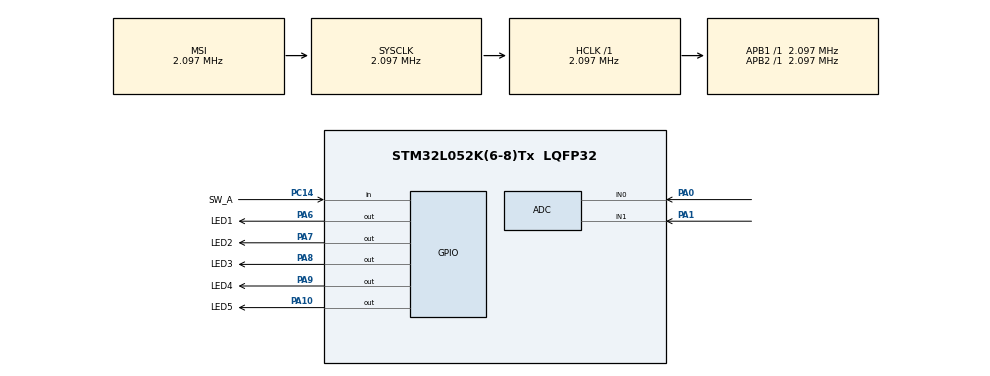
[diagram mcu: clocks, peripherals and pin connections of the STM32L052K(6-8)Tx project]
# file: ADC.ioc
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ADC.SamplingTime=ADC_SAMPLETIME_160CYCLES_5
Mcu.Family=STM32L0
Mcu.Name=STM32L052K(6-8)Tx
Mcu.Package=LQFP32
PA0.Mode=IN0
PA0.Signal=ADC_IN0
PA1.Mode=IN1
PA1.Signal=ADC_IN1
PA10.GPIO_Label=LED5
PA10.Signal=GPIO_Output
PA13.Mode=Serial_Wire
PA13.Signal=SYS_SWDIO
PA14.Mode=Serial_Wire
PA14.Signal=SYS_SWCLK
PA6.GPIO_Label=LED1
PA6.Signal=GPIO_Output
PA7.GPIO_Label=LED2
PA7.Signal=GPIO_Output
PA8.GPIO_Label=LED3
PA8.Signal=GPIO_Output
PA9.GPIO_Label=LED4
PA9.Signal=GPIO_Output
PC14-OSC32_IN.GPIO_Label=SW_A
PC14-OSC32_IN.GPIO_PuPd=GPIO_PULLUP
PC14-OSC32_IN.Signal=GPIO_Input
ProjectManager.HeapSize=0x200
ProjectManager.StackSize=0x400
ProjectManager.TargetToolchain=STM32CubeIDE
RCC.AHBFreq_Value=2097000
RCC.APB1Freq_Value=2097000
RCC.APB1TimFreq_Value=2097000
RCC.APB2Freq_Value=2097000
RCC.APB2TimFreq_Value=2097000
RCC.HSI16_VALUE=16000000
RCC.HSI48_VALUE=48000000
RCC.HSI_VALUE=16000000
RCC.LSE_VALUE=32768
RCC.MSI_VALUE=2097000
RCC.SYSCLKFreq_VALUE=2097000
RCC.VCOOutputFreq_Value=48000000
board=custom

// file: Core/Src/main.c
/* USER CODE BEGIN Header */
/**
 ******************************************************************************
 * @file           : main.c
 * @brief          : Main program body
 ******************************************************************************
 * @attention
 *
 * Copyright (c) 2022 STMicroelectronics.
 * All rights reserved.
 *
 * This software is licensed under terms that can be found in the LICENSE file
 * in the root directory of this software component.
 * If no LICENSE file comes with this software, it is provided AS-IS.
 *
 ******************************************************************************
 */
/* USER CODE END Header */
#include "main.h"

/* USER CODE BEGIN PTD */
enum _bool{false, true};
typedef uint8_t boolean;
/* USER CODE END PTD */

/* USER CODE BEGIN PD */
#define SW4 HAL_GPIO_ReadPin(SW_A_GPIO_Port, SW_A_Pin)
#define LED(N, X) HAL_GPIO_WritePin(LED##N##_GPIO_Port, LED##N##_Pin, (!X))
/* USER CODE END PD */

ADC_HandleTypeDef hadc;

void SystemClock_Config(void);
static void MX_GPIO_Init(void);
static void MX_ADC_Init(void);

/* USER CODE BEGIN 0 */
void read_ADC(uint16_t *cds, uint16_t *vr){
	HAL_ADC_Start(&hadc);
	HAL_ADC_PollForConversion(&hadc, 1000);
	*cds = HAL_ADC_GetValue(&hadc);
	HAL_ADC_PollForConversion(&hadc, 1000);
	*vr = HAL_ADC_GetValue(&hadc);
	HAL_ADC_Stop(&hadc);
}
/* USER CODE END 0 */

int main(void) {
	/* USER CODE BEGIN 1 */
	uint16_t cds, vr;
	/* USER CODE END 1 */
	/* MCU Configuration--------------------------------------------------------*/

	/* Reset of all peripherals, Initializes the Flash interface and the Systick. */
	HAL_Init();

	/* Configure the system clock */
	SystemClock_Config();

	/* Initialize all configured peripherals */
	MX_GPIO_Init();
	MX_ADC_Init();

	/* Infinite loop */
	while (1) {
		read_ADC(&cds, &vr);
		vr = (uint16_t)((double)vr / 1023.75);
		LED(1, (vr == 0 || cds > 4000));
		LED(2, (vr == 1 || cds > 4000));
		LED(3, (vr == 2 || cds > 4000));
		LED(4, (vr == 3 || cds > 4000));
		LED(5, (vr == 4 || cds > 4000));

	}
}

void SystemClock_Config(void) {
	RCC_OscInitTypeDef RCC_OscInitStruct = { 0 };
	RCC_ClkInitTypeDef RCC_ClkInitStruct = { 0 };

	/** Configure the main internal regulator output voltage
	 */
	__HAL_PWR_VOLTAGESCALING_CONFIG(PWR_REGULATOR_VOLTAGE_SCALE1);

	/** Initializes the RCC Oscillators according to the specified parameters
	 * in the RCC_OscInitTypeDef structure.
	 */
	RCC_OscInitStruct.OscillatorType = RCC_OSCILLATORTYPE_MSI;
	RCC_OscInitStruct.MSIState = RCC_MSI_ON;
	RCC_OscInitStruct.MSICalibrationValue = 0;
	RCC_OscInitStruct.MSIClockRange = RCC_MSIRANGE_5;
	RCC_OscInitStruct.PLL.PLLState = RCC_PLL_NONE;
	if (HAL_RCC_OscConfig(&RCC_OscInitStruct) != HAL_OK) {
		Error_Handler();
	}

	/** Initializes the CPU, AHB and APB buses clocks
	 */
	RCC_ClkInitStruct.ClockType = RCC_CLOCKTYPE_HCLK | RCC_CLOCKTYPE_SYSCLK
			| RCC_CLOCKTYPE_PCLK1 | RCC_CLOCKTYPE_PCLK2;
	RCC_ClkInitStruct.SYSCLKSource = RCC_SYSCLKSOURCE_MSI;
	RCC_ClkInitStruct.AHBCLKDivider = RCC_SYSCLK_DIV1;
	RCC_ClkInitStruct.APB1CLKDivider = RCC_HCLK_DIV1;
	RCC_ClkInitStruct.APB2CLKDivider = RCC_HCLK_DIV1;

	if (HAL_RCC_ClockConfig(&RCC_ClkInitStruct, FLASH_LATENCY_0) != HAL_OK) {
		Error_Handler();
	}
}

static void MX_ADC_Init(void) {

	ADC_ChannelConfTypeDef sConfig = { 0 };

	/** Configure the global features of the ADC (Clock, Resolution, Data Alignment and number of conversion)
	 */
	hadc.Instance = ADC1;
	hadc.Init.OversamplingMode = DISABLE;
	hadc.Init.ClockPrescaler = ADC_CLOCK_SYNC_PCLK_DIV1;
	hadc.Init.Resolution = ADC_RESOLUTION_12B;
	hadc.Init.SamplingTime = ADC_SAMPLETIME_160CYCLES_5;
	hadc.Init.ScanConvMode = ADC_SCAN_DIRECTION_FORWARD;
	hadc.Init.DataAlign = ADC_DATAALIGN_RIGHT;
	hadc.Init.ContinuousConvMode = DISABLE;
	hadc.Init.DiscontinuousConvMode = DISABLE;
	hadc.Init.ExternalTrigConvEdge = ADC_EXTERNALTRIGCONVEDGE_NONE;
	hadc.Init.ExternalTrigConv = ADC_SOFTWARE_START;
	hadc.Init.DMAContinuousRequests = DISABLE;
	hadc.Init.EOCSelection = ADC_EOC_SINGLE_CONV;
	hadc.Init.Overrun = ADC_OVR_DATA_PRESERVED;
	hadc.Init.LowPowerAutoWait = DISABLE;
	hadc.Init.LowPowerFrequencyMode = ENABLE;
	hadc.Init.LowPowerAutoPowerOff = DISABLE;
	if (HAL_ADC_Init(&hadc) != HAL_OK) {
		Error_Handler();
	}

	/** Configure for the selected ADC regular channel to be converted.
	 */
	sConfig.Channel = ADC_CHANNEL_0;
	sConfig.Rank = ADC_RANK_CHANNEL_NUMBER;
	if (HAL_ADC_ConfigChannel(&hadc, &sConfig) != HAL_OK) {
		Error_Handler();
	}

	/** Configure for the selected ADC regular channel to be converted.
	 */
	sConfig.Channel = ADC_CHANNEL_1;
	if (HAL_ADC_ConfigChannel(&hadc, &sConfig) != HAL_OK) {
		Error_Handler();
	}

}

static void MX_GPIO_Init(void) {
	GPIO_InitTypeDef GPIO_InitStruct = { 0 };

	/* GPIO Ports Clock Enable */
	__HAL_RCC_GPIOC_CLK_ENABLE();
	__HAL_RCC_GPIOA_CLK_ENABLE();

	/*Configure GPIO pin Output Level */
	HAL_GPIO_WritePin(GPIOA,
			LED1_Pin | LED2_Pin | LED3_Pin | LED4_Pin | LED5_Pin,
			GPIO_PIN_RESET);

	/*Configure GPIO pin : SW_A_Pin */
	GPIO_InitStruct.Pin = SW_A_Pin;
	GPIO_InitStruct.Mode = GPIO_MODE_INPUT;
	GPIO_InitStruct.Pull = GPIO_PULLUP;
	HAL_GPIO_Init(SW_A_GPIO_Port, &GPIO_InitStruct);

	/*Configure GPIO pins : LED1_Pin LED2_Pin LED3_Pin LED4_Pin
	 LED5_Pin */
	GPIO_InitStruct.Pin = LED1_Pin | LED2_Pin | LED3_Pin | LED4_Pin | LED5_Pin;
	GPIO_InitStruct.Mode = GPIO_MODE_OUTPUT_PP;
	GPIO_InitStruct.Pull = GPIO_NOPULL;
	GPIO_InitStruct.Speed = GPIO_SPEED_FREQ_LOW;
	HAL_GPIO_Init(GPIOA, &GPIO_InitStruct);

}

void Error_Handler(void) {
	__disable_irq();
	while (1) {
	}
}
